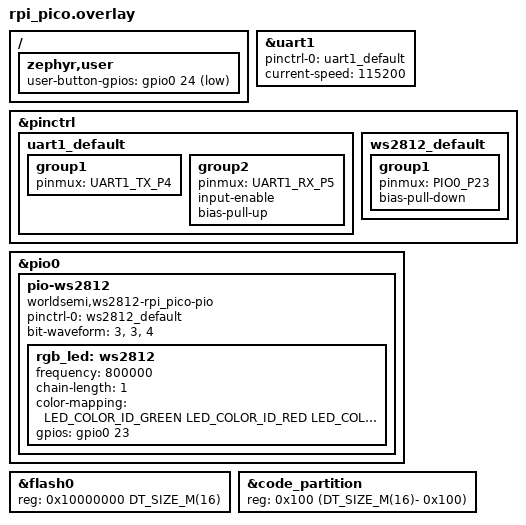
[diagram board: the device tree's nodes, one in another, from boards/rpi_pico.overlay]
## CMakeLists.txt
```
cmake_minimum_required(VERSION 3.28.0)

find_package(Zephyr)
project(zephyr-example-uart)

target_sources(app PRIVATE
    src/main.c
    src/button.c
    src/uart_link.c
  )
```

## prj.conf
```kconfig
# Copyright (c) 2026, Marcio Bulla
#
# SPDX-License-Identifier: Apache-2.0

CONFIG_LOG=y
CONFIG_NET_BUF=y
CONFIG_POLL=y
```

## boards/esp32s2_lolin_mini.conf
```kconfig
# Copyright (c) 2026, Marcio Bulla
#
# SPDX-License-Identifier: Apache-2.0

CONFIG_UART_INTERRUPT_DRIVEN=y
```

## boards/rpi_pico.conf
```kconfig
# Copyright (c) 2026, Marcio Bulla
#
# SPDX-License-Identifier: Apache-2.0

# CONFIG_LED_STRIP=y
```

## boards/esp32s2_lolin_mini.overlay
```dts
#include <zephyr/dt-bindings/pinctrl/esp32s2-pinctrl.h>
#include <zephyr/dt-bindings/gpio/gpio.h>

/ {
  zephyr,user{
    user-button-gpios = <&gpio0 0 (GPIO_PULL_UP | GPIO_ACTIVE_LOW)>;
  };
};


&uart1 {
  pinctrl-0 = <&uart1_default>;
  current-speed = <115200>;
  pinctrl-names = "default";
  status = "okay";
};

&pinctrl {
  uart1_default: uart1_default {
    group1 {
      pinmux = <UART1_TX_GPIO5>;
      output-high;
    };

    group2 {
      pinmux = <UART1_RX_GPIO7>;
      bias-pull-up;
    };
  };
};
```

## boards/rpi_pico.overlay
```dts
#include <zephyr/dt-bindings/pinctrl/rpi-pico-pinctrl-common.h>
#include <zephyr/dt-bindings/gpio/gpio.h>
#include <zephyr/dt-bindings/led/led.h>
#include <common/mem.h>

/ {
  zephyr,user{
    user-button-gpios = <&gpio0 24 (GPIO_PULL_UP | GPIO_ACTIVE_LOW)>;
  };
};

&uart1 {
  pinctrl-0 = <&uart1_default>;
  current-speed = <115200>;
  pinctrl-names = "default";
  status = "okay";
};

&pinctrl {
  uart1_default: uart1_default {
    group1 {
      pinmux = <UART1_TX_P4>;
    };

    group2 {
      pinmux = <UART1_RX_P5>;
      input-enable;
      bias-pull-up;
    };
  };

  ws2812_default: ws2812_default {
    group1 {
      pinmux = <PIO0_P23>;
      bias-pull-down;
    };
  };
};

&pio0 {
  status = "okay";

  pio-ws2812 {
    compatible = "worldsemi,ws2812-rpi_pico-pio";

    pinctrl-0 = <&ws2812_default>;
    pinctrl-names = "default";

    bit-waveform = <3>, <3>, <4>;

    rgb_led: ws2812 {
      frequency = <800000>;
      chain-length = <1>;
      color-mapping = <LED_COLOR_ID_GREEN
                    LED_COLOR_ID_RED
                    LED_COLOR_ID_BLUE>;
      gpios = <&gpio0 23 GPIO_ACTIVE_HIGH>;
    };
  };
};

&flash0 {
  reg = < 0x10000000 DT_SIZE_M(16) >;
  ranges = < 0x0 0x10000000 DT_SIZE_M(16) >;
};

&code_partition {
  reg = <0x100 (DT_SIZE_M(16)- 0x100)>;
};
```

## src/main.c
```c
/*
 * Copyright (c) 2026, Marcio Bulla
 *
 * SPDX-License-Identifier: Apache-2.0
 */

#include "button.h"
#include "uart_link.h"
#include <stdbool.h>
#include <stddef.h>
#include <stdint.h>
#include <sys/errno.h>
#include <zephyr/device.h>
#include <zephyr/devicetree.h>
#include <zephyr/drivers/gpio.h>
#include <zephyr/logging/log.h>
#include <zephyr/sys/printk.h>

LOG_MODULE_REGISTER(app, LOG_LEVEL_INF);

static const char board[] = CONFIG_BOARD_TARGET;

#define LED0_NODE DT_ALIAS(led0)

static const struct gpio_dt_spec led = GPIO_DT_SPEC_GET(LED0_NODE, gpios);

static void app_rx_byte(const uint8_t *data, size_t len, const void *user_data) {
  const struct gpio_dt_spec *led = user_data;

  printk("%.*s\n", (int)len, (const char *)data);

  gpio_pin_toggle_dt(led);
}

int main(void) {

  if (!gpio_is_ready_dt(&led)) {
    printk("LED0 not ready\n");
    return -ENODEV;
  }

  int ret;

  ret = gpio_pin_configure_dt(&led, GPIO_OUTPUT_INACTIVE);
  if (ret != 0) {
    printk("Pin Led Configure error!\n");
    return ret;
  }

  ret = button_init();
  if (ret < 0) {
    LOG_ERR("Failed to initialize button: %d", ret);
    return ret;
  }

  ret = uart1_init(app_rx_byte, &led);
  if (ret < 0) {
    LOG_ERR("Failed to initialize UART1: %d", ret);
    return ret;
  }

  uint8_t len = sizeof(board);

  uint8_t text_msg[sizeof(board) + 4];

  text_msg[0] = 0x14;
  text_msg[1] = len;

  memcpy(&text_msg[2], board, sizeof(board) - 1);

  text_msg[sizeof(board) + 1] = '\n';
  text_msg[sizeof(board) + 2] = 0xFF;
  text_msg[sizeof(board) + 3] = 0xFF;

  size_t size_msg = sizeof(text_msg);

  while (true) {
    ret = button_wait_press();
    if (ret < 0) {
      LOG_ERR("Failed to wait for button press: %d", ret);
      return ret;
    }

    uart1_send(text_msg, size_msg);
  }

  return 0;
}
```

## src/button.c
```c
/*
 * @file button.c
 * @brief implementation of button's configuration and application.
 *
 * Copyright (c) 2026, Marcio Bulla
 *
 * SPDX-License-Identifier: Apache-2.0
 */

#include "button.h"
#include <sys/errno.h>
#include <zephyr/drivers/gpio.h>
#include <zephyr/kernel.h>
#include <zephyr/logging/log.h>
#include <zephyr/sys/util_macro.h>

LOG_MODULE_REGISTER(button, LOG_LEVEL_INF);

#define ZEPHYR_USER_NODE DT_PATH(zephyr_user)

static const struct gpio_dt_spec user_button =
    GPIO_DT_SPEC_GET(ZEPHYR_USER_NODE, user_button_gpios);

static struct gpio_callback user_button_cb_data;

static K_SEM_DEFINE(press_sem, 0, 10);

static void user_button_work_handler(struct k_work *work) {
  if (gpio_pin_get_dt(&user_button) == 1) {
    k_sem_give(&press_sem);
  }
}

K_WORK_DELAYABLE_DEFINE(user_button_work, user_button_work_handler);

static void user_button_cb(const struct device *port, struct gpio_callback *cb,
                           gpio_port_pins_t pins) {
  k_work_reschedule(&user_button_work, K_MSEC(30));
}

int button_init(void) {
  int ret;

  if (!gpio_is_ready_dt(&user_button)) {
    LOG_ERR("Button GPIO device is not ready");
    return -ENODEV;
  }

  ret = gpio_pin_configure_dt(&user_button, GPIO_INPUT);
  if (ret < 0) {
    LOG_ERR("Failed to configure button GPIO: %d", ret);
    return ret;
  }

  gpio_init_callback(&user_button_cb_data, &user_button_cb,
                     BIT(user_button.pin));

  ret = gpio_add_callback(user_button.port, &user_button_cb_data);
  if (ret < 0) {
    LOG_ERR("Failed to add button callback %d", ret);
    return ret;
  }

  ret = gpio_pin_interrupt_configure_dt(&user_button, GPIO_INT_EDGE_TO_ACTIVE);
  if (ret < 0) {
    LOG_ERR("Failed to configure button interrupt %d", ret);
    return ret;
  }

  return 0;
}

int button_wait_press(void) {
  int ret;

  ret = k_sem_take(&press_sem, K_FOREVER);
  if (ret < 0) {
    LOG_ERR("Failed to take button semaphore: %d", ret);
    return ret;
  }

  return 0;
}
```

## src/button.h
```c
/*
 *  @file button.h
 *  @brief Button configuration and Function.
 *
 * Copyright (c) 2026, Marcio Bulla
 *
 * SPDX-License-Identifier: Apache-2.0
 */

#ifndef BUTTON_H_
#define BUTTON_H_

/**
 * @brief Initialize the button.
 *
 * @return 0 on success, or a negative error code on failure.
 */
int button_init(void);


/**
 * @brief Block the calling thread until a debounced button press.
 *
 * @return 0 when a button press is received.
 */
int button_wait_press(void);

#endif /* BUTTON_H_ */
```

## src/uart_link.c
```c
/**
 *  @file uart_link.c
 *  @brief UART1 transport with interrupt-driven RX and TX.
 *
 * Copyright (c) 2026, Marcio Bulla
 *
 * SPDX-License-Identifier: Apache-2.0
 */

#include "uart_link.h"
#include <stddef.h>
#include <stdint.h>
#include <stdio.h>
#include <string.h>
#include <sys/errno.h>
#include <zephyr/drivers/uart.h>
#include <zephyr/kernel.h>
#include <zephyr/logging/log.h>
#include <zephyr/net_buf.h>

#define UART_TIMEOUT_US                                                        \
  (3U * 10U * 1000000U / DT_PROP(DT_NODELABEL(uart1), current_speed))

LOG_MODULE_REGISTER(uart_link, LOG_LEVEL_INF);

#define UART1_NODE DT_NODELABEL(uart1)

static const struct device *const uart1 = DEVICE_DT_GET(UART1_NODE);

static uart_link_rx_byte_cb_t rx_callback;
static const void *rx_context;

K_FIFO_DEFINE(rx_fifo);
K_FIFO_DEFINE(tx_fifo);
K_SEM_DEFINE(rx_loss_sem, 0, 1);

NET_BUF_POOL_VAR_DEFINE(rx_pool, 4, 1 + 1 + 255 + 2, 0, NULL);
NET_BUF_POOL_VAR_DEFINE(tx_pool, 4, 1 + 1 + 255 + 2, 0, NULL);

enum frame_state_t {
  STATE_WAIT_START,
  STATE_READ_LEN,
  STATE_READ_DATA,
};

static void uart1_isr(const struct device *dev, void *user_data) {
  uart_irq_update(uart1);

  if (uart_irq_tx_ready(uart1)) {
    static struct net_buf *tx_buf;
    int tx_len;

    if (!tx_buf) {
      tx_buf = k_fifo_get(&tx_fifo, K_NO_WAIT);
    }
    if (!tx_buf) {
      uart_irq_tx_disable(uart1);
    } else {

      tx_len = uart_fifo_fill(uart1, tx_buf->data, tx_buf->len);
      if (tx_len > 0) {
        net_buf_pull(tx_buf, tx_len);
        if (!tx_buf->len) {
          net_buf_unref(tx_buf);
          tx_buf = NULL;
        }
      }
    }
  }

  if (uart_irq_rx_ready(uart1)) {
    static struct net_buf *rx_buf;
    static enum frame_state_t state = STATE_WAIT_START;
    static uint16_t rx_len;
    uint8_t byte;

    while (uart_fifo_read(uart1, &byte, 1) > 0) {
      switch (state) {
      case STATE_WAIT_START:
        if (byte == 0x14) {
          state = STATE_READ_LEN;
        }
        break;

      case STATE_READ_LEN:
        if (byte == 0U) {
          state = STATE_WAIT_START;
          break;
        }

        rx_len = byte + 2;
        rx_buf = net_buf_alloc_len(&rx_pool, rx_len, K_NO_WAIT);
        if (rx_buf) {
          state = STATE_READ_DATA;
        } else {
          k_sem_give(&rx_loss_sem);
          state = STATE_WAIT_START;
        }
        break;

      case STATE_READ_DATA:
        net_buf_add_u8(rx_buf, byte);
        if (--rx_len == 0) {
          k_fifo_put(&rx_fifo, rx_buf);
          rx_buf = NULL;
          state = STATE_WAIT_START;
        }
        break;
      }
    }
  }
}

static void rx_read_entry(void *p1, void *p2, void *p3) {
  static struct net_buf *msg_buf;
  struct k_poll_event rx_events[2];

  k_poll_event_init(&rx_events[0], K_POLL_TYPE_FIFO_DATA_AVAILABLE,
                    K_POLL_MODE_NOTIFY_ONLY, &rx_fifo);

  k_poll_event_init(&rx_events[1], K_POLL_TYPE_SEM_AVAILABLE,
                    K_POLL_MODE_NOTIFY_ONLY, &rx_loss_sem);

  while (true) {
    rx_events[0].state = K_POLL_STATE_NOT_READY;
    rx_events[1].state = K_POLL_STATE_NOT_READY;

    int ret = k_poll(rx_events, 2, K_FOREVER);
    if (ret != 0) {
      continue;
    }

    if (k_sem_take(&rx_loss_sem, K_NO_WAIT) == 0) {
      struct net_buf *discarded;

      while ((discarded = k_fifo_get(&rx_fifo, K_NO_WAIT)) != NULL) {
        net_buf_unref(discarded);
      }

      LOG_WRN("Lost a message");
      continue;
    }

    msg_buf = k_fifo_get(&rx_fifo, K_NO_WAIT);
    if (!msg_buf) {
      continue;
    }

    rx_callback(msg_buf->data, msg_buf->len, rx_context);

    net_buf_pull(msg_buf, msg_buf->len);
    if (!msg_buf->len) {
      net_buf_unref(msg_buf);
      msg_buf = NULL;
    }
  }
}

K_THREAD_DEFINE(rx_read_tid, 1024, &rx_read_entry, NULL, NULL, NULL, 5, 0, 0);

int uart1_init(uart_link_rx_byte_cb_t on_byte, const void *user_data) {
  rx_callback = on_byte;
  rx_context = user_data;
  int ret;

  if (!device_is_ready(uart1)) {
    printk("UART1 not Ready\n");
    return -ENODEV;
  }

  ret = uart_irq_callback_user_data_set(uart1, &uart1_isr, NULL);
  if (ret != 0) {
    LOG_ERR("Failed to set IRQ on uart1: %d", ret);
    return ret;
  }

  uart_irq_rx_enable(uart1);

  return 0;
}

int uart1_send(char *text_msg, size_t size_msg) {
  if (text_msg == NULL || size_msg == 0) {
    LOG_WRN("Empty message");
    return -EINVAL;
  }

  if (size_msg > 259U) {
    LOG_WRN("Message too large");
    return -EMSGSIZE;
  }

  struct net_buf *buf;

  buf = net_buf_alloc_len(&tx_pool, size_msg, K_NO_WAIT);
  if (!buf) {
    LOG_ERR("Failed to allocate buffer");
    return -ENOMEM;
  }

  net_buf_add_mem(buf, text_msg, size_msg);
  k_fifo_put(&tx_fifo, buf);
  uart_irq_tx_enable(uart1);

  return 0;
}
```

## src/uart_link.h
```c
/**
 *  @file uart_link.h
 *  @brief Interface for the UART1 link.
 *
 * Copyright (c) 2026, Marcio Bulla
 *
 * SPDX-License-Identifier: Apache-2.0
 */

#ifndef UART_LINK_H_
#define UART_LINK_H_

#include <stddef.h>
#include <stdint.h>

/**
 * @brief Handle a received UART1 message candidate.
 *
 * Called from the RX thread after the current receiver has collected the
 * declared number of data bytes. The buffer is not validated by this module
 * and is valid only until the callback returns.
 *
 * @param data Received bytes; not guaranteed to be null-terminated.
 * @param len Number of valid bytes in @p data.
 * @param user_data Context provided to uart1_init().
 */
typedef void (*uart_link_rx_byte_cb_t)(const uint8_t *data, size_t len,
                                      const void *user_data);

/**
 * @brief Initialize UART1 and enable interrupt-driven reception.
 *
 * The callback and its context are retained and used by the RX thread.
 *
 * @param on_byte Callback invoked for each received message candidate; must
 *                not be NULL.
 * @param user_data Context passed unchanged to @p on_byte.
 *
 * @return 0 on success, or a negative error code on failure.
 */
int uart1_init(uart_link_rx_byte_cb_t on_byte, const void *user_data);

/**
 * @brief Queue @p size_msg bytes for interrupt-driven transmission on UART1.
 *
 * The bytes are queued as provided. This function does not append framing,
 * CRC, a string terminator, or a delimiter. A successful return indicates
 * that the data was queued, not that transmission has finished.
 *
 * @param text_msg Buffer containing the bytes to send.
 * @param size_msg Number of bytes to send.
 *
 * @return 0 if queued, -EINVAL for an empty message, -EMSGSIZE if too large,
 *         or -ENOMEM if a transmit buffer is unavailable.
 */
int uart1_send(char text_msg[], size_t size_msg);


#endif /* UART_LINK_H_ */
```
